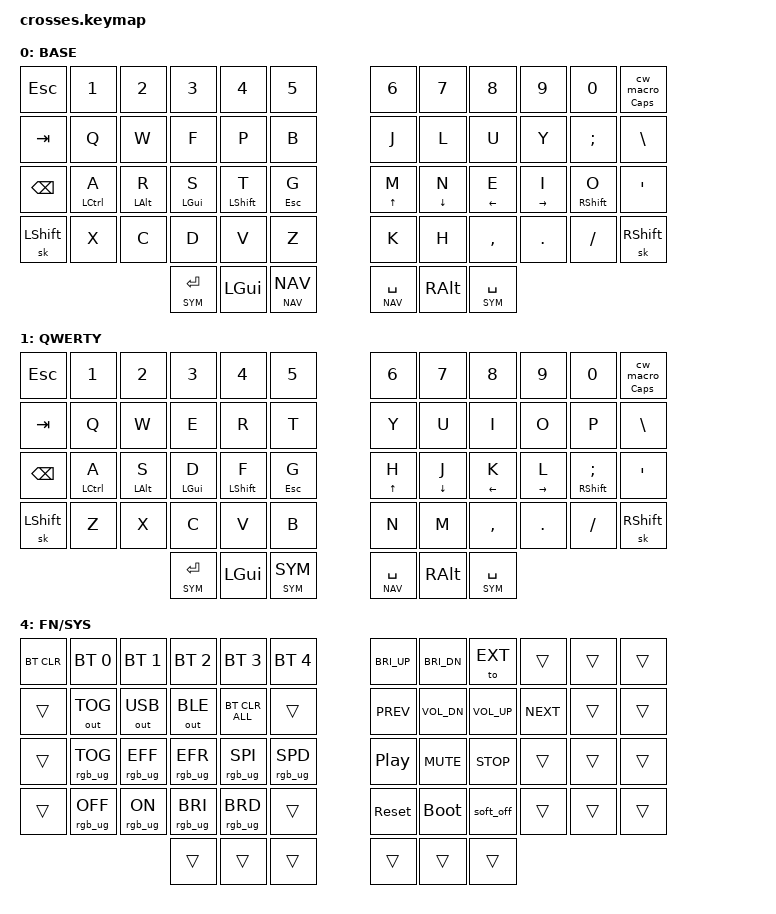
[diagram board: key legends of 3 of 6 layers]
#include <behaviors.dtsi>
#include <dt-bindings/zmk/bt.h>
#include <dt-bindings/zmk/keys.h>
#include <dt-bindings/zmk/outputs.h>
#include <dt-bindings/zmk/pointing.h>
#include <dt-bindings/zmk/rgb.h>
#include <input/processors.dtsi>

#define BASE   0
#define QWERTY 1
#define NAV    2
#define SYM    3
#define FN     4
#define EXT    5

#define LMODS  &kp LCTRL &kp LALT &kp LGUI &kp LSHFT
#define EDIT   &kp K_UNDO &kp K_CUT &kp K_COPY &kp K_PASTE &kp K_REDO

&soft_off { hold-time-ms = <2000>; };

&caps_word { continue-list = <UNDERSCORE MINUS BACKSPACE DELETE>; };

&sk { ignore-modifiers; };

/ {
    chosen { zmk,physical-layout = &gggw_crosses_54_layout; };

    conditional_layers {
        compatible = "zmk,conditional-layers";
        tri_layer {
            if-layers = <NAV SYM>;
            then-layer = <FN>;
        };
    };

    macros {
        cw_macro: cw_macro {
            compatible = "zmk,behavior-macro-one-param";
            #binding-cells = <1>;
            bindings = <&caps_word>;
        };
    };

    behaviors {
        hml: home_row_mod_left {
            compatible = "zmk,behavior-hold-tap";
            #binding-cells = <2>;
            flavor = "balanced";
            tapping-term-ms = <220>;
            quick-tap-ms = <175>;
            require-prior-idle-ms = <150>;
            bindings = <&sk>, <&kp>;
            hold-trigger-key-positions = <
                6  7  8  9  10 11 
                18 19 20 21 22 23 
                30 31 32 33 34 35 
                42 43 44 45 46 47 
                51 52 53
                25 26 27 28
            >;
            hold-trigger-on-release;
        };

        hsl: home_shift_left {
            compatible = "zmk,behavior-hold-tap";
            #binding-cells = <2>;
            flavor = "balanced";
            tapping-term-ms = <220>;
            quick-tap-ms = <175>;
            require-prior-idle-ms = <0>;
            bindings = <&sk>, <&kp>;
            hold-trigger-key-positions = <
                6  7  8  9  10 11 
                18 19 20 21 22 23 
                30 31 32 33 34 35 
                42 43 44 45 46 47 
                51 52 53
                25 26 27 28
            >;
            hold-trigger-on-release;
        };

        hmr: home_row_mod_right {
            compatible = "zmk,behavior-hold-tap";
            #binding-cells = <2>;
            flavor = "balanced";
            tapping-term-ms = <220>;
            quick-tap-ms = <175>;
            require-prior-idle-ms = <0>;
            bindings = <&sk>, <&kp>;
            hold-trigger-key-positions = <
                0  1  2  3  4  5
                12 13 14 15 16 17
                24 25 26 27 28 29
                36 37 38 39 40 41
                48 49 50
            >;
            hold-trigger-on-release;
        };

        hra: home_row_arrow {
            compatible = "zmk,behavior-hold-tap";
            #binding-cells = <2>;
            flavor = "balanced";
            tapping-term-ms = <200>;
            quick-tap-ms = <175>;
            require-prior-idle-ms = <150>;
            bindings = <&kp>, <&kp>;
            hold-trigger-key-positions = <
                0  1  2  3  4  5
                12 13 14 15 16 17
                24 25 26 27 28 29
                36 37 38 39 40 41
                48 49 50
            >;
            hold-trigger-on-release;
        };

        hla: home_left_arrow {
            compatible = "zmk,behavior-hold-tap";
            #binding-cells = <2>;
            flavor = "balanced";
            tapping-term-ms = <200>;
            quick-tap-ms = <175>;
            require-prior-idle-ms = <0>;
            bindings = <&kp>, <&kp>;
            hold-trigger-key-positions = <
                6  7  8  9  10 11 
                18 19 20 21 22 23 
                30 31 32 33 34 35 
                42 43 44 45 46 47 
                51 52 53
            >;
            hold-trigger-on-release;
        };

        lt_thumb: layer_tap_thumb {
            compatible = "zmk,behavior-hold-tap";
            #binding-cells = <2>;
            flavor = "tap-preferred";
            tapping-term-ms = <180>;
            quick-tap-ms = <150>;
            bindings = <&mo>, <&kp>;
        };

        ltq: layer_tap_or_sticky {
            compatible = "zmk,behavior-hold-tap";
            #binding-cells = <2>;
            flavor = "balanced";
            tapping-term-ms = <200>;
            quick-tap-ms = <0>;
            bindings = <&mo>, <&sl>;
        };

        kp_slh: kp_tap_sticky_layer_hold {
            compatible = "zmk,behavior-hold-tap";
            #binding-cells = <2>;
            flavor = "balanced";
            tapping-term-ms = <150>;
            quick-tap-ms = <120>;
            require-prior-idle-ms = <100>;
            bindings = <&sl>, <&kp>;
        };

        cw_caps: caps_word_tap_caps_hold {
            compatible = "zmk,behavior-hold-tap";
            #binding-cells = <2>;
            flavor = "tap-preferred";
            tapping-term-ms = <200>;
            quick-tap-ms = <150>;
            bindings = <&kp>, <&cw_macro>;
        };
    };

    keymap {
        compatible = "zmk,keymap";

        base_layer {
            display-name = "BASE";
            bindings = <
&kp ESC        &kp N1         &kp N2         &kp N3        &kp N4              &kp N5            &kp N6              &kp N7         &kp N8        &kp N9         &kp N0            &cw_caps CAPS 0
&kp TAB        &kp Q          &kp W          &kp F         &kp P               &kp B             &kp J               &kp L          &kp U         &kp Y          &kp SEMI          &kp BSLH
&kp BACKSPACE  &hml LCTRL A   &hml LALT R   &hml LGUI S   &hsl LSHFT T         &hla ESC G        &hra UP M           &hra DOWN N    &hra LEFT E   &hra RIGHT I   &hmr RSHFT O      &kp APOS
&sk LSHFT      &kp X          &kp C          &kp D         &kp V               &kp Z             &kp K               &kp H          &kp COMMA     &kp DOT        &kp FSLH          &sk RSHFT
                                            &kp_slh SYM ENTER &kp LGUI        &ltq NAV NAV       &kp_slh NAV SPACE   &kp RALT             &lt_thumb SYM SPACE
            >;
        };

        qwerty_layer {
            display-name = "QWERTY";
            bindings = <
&kp ESC    &kp N1         &kp N2        &kp N3         &kp N4              &kp N5            &kp N6              &kp N7         &kp N8        &kp N9         &kp N0            &cw_caps CAPS 0
&kp TAB    &kp Q          &kp W         &kp E          &kp R               &kp T             &kp Y               &kp U          &kp I         &kp O          &kp P             &kp BSLH
&kp BACKSPACE  &hml LCTRL A   &hml LALT S   &hml LGUI D   &hsl LSHFT F  &hla ESC G        &hra UP H          &hra DOWN J      &hra LEFT K   &hra RIGHT L    &hmr RSHFT SEMI   &kp APOS
&sk LSHFT  &kp Z          &kp X         &kp C          &kp V               &kp B             &kp N               &kp M          &kp COMMA     &kp DOT        &kp FSLH          &sk RSHFT
                                        &kp_slh SYM ENTER &kp LGUI         &ltq SYM SYM      &kp_slh NAV SPACE   &kp RALT              &lt_thumb SYM SPACE
            >;
        };

        nav_layer {
            display-name = "NAV";
            bindings = <
&trans     &kp F1      &kp F2      &kp F3      &kp F4      &kp F5      &kp F6      &kp F7     &kp F8     &kp F9     &kp F10     &kp F11
&trans     &kp ESC     &mkp LCLK   &mkp MCLK   &mkp RCLK   &mkp MB4    &kp PG_UP   &kp N7     &kp N8     &kp N9     &kp MINUS   &kp F12
&trans     LMODS                                           &mkp MB5    &kp N4     &kp N5     &kp N6     &kp PLUS    &kp EQUAL
&trans     EDIT                                                        &kp N1     &kp N2     &kp N3     &kp ASTRK   &kp ENTER
                                   &trans      &trans      &trans      &trans     &kp DOT    &kp N0
            >;
        };

        sym_layer {
            display-name = "SYM";
            bindings = <
&trans     &kp N1      &kp N2      &kp N3      &kp N4      &kp N5      &kp N6       &kp N7       &kp N8       &kp N9       &kp N0       &trans
&kp TILDE  &kp EXCL    &kp AT      &kp HASH    &kp DLLR    &kp PRCNT   &kp CARET    &kp AMPS     &kp ASTRK    &kp LPAR     &kp RPAR     &kp COLON
&kp GRAVE  LMODS                                           &kp DQT     &kp PLUS     &kp EQUAL    &kp LBRC     &kp RBRC     &kp MINUS    &kp SEMI
&trans     &kp UNDER   &kp LT      &tog QWERTY &kp GT      &kp BSLH    &kp SLASH    &kp QMARK    &kp LBKT     &kp RBKT     &kp UNDER    &trans
                                   &trans      &trans      &trans      &trans       &trans       &trans
            >;
        };

        fn_layer {
            display-name = "FN/SYS";
            bindings = <
&bt BT_CLR &bt BT_SEL 0     &bt BT_SEL 1      &bt BT_SEL 2     &bt BT_SEL 3     &bt BT_SEL 4      &kp C_BRI_UP  &kp C_BRI_DN  &to EXT      &trans  &trans  &trans
&trans     &out OUT_TOG     &out OUT_USB      &out OUT_BLE     &bt BT_CLR_ALL   &trans            &kp C_PREV    &kp C_VOL_DN  &kp C_VOL_UP &kp C_NEXT &trans &trans
&trans     &rgb_ug RGB_TOG  &rgb_ug RGB_EFF   &rgb_ug RGB_EFR  &rgb_ug RGB_SPI  &rgb_ug RGB_SPD   &kp C_PP      &kp C_MUTE    &kp C_STOP   &trans  &trans  &trans
&trans     &rgb_ug RGB_OFF  &rgb_ug RGB_ON    &rgb_ug RGB_BRI  &rgb_ug RGB_BRD  &trans            &sys_reset    &bootloader   &soft_off    &trans  &trans  &trans
                                              &trans           &trans           &trans            &trans        &trans        &trans
            >;
        };

        ext_layer {
            display-name = "EXT";
            bindings = <
&to BASE   &kp PSCRN     &kp SLCK      &kp PAUSE_BREAK  &kp KP_NUM    &trans          &kp INS       &kp HOME      &kp PG_UP     &trans        &trans        &trans
&trans     &kp F11       &kp F12       &kp K_APP        &kp CAPS      &trans          &kp DEL       &kp END       &kp PG_DN     &trans        &trans        &trans
&trans     LMODS                                                      &trans          &kp LEFT      &kp DOWN      &kp UP        &kp RIGHT     &trans        &trans
&trans     EDIT                                                                       &kp K_FIND    &kp C_AL_LOCK &trans        &trans        &trans        &trans
                                       &to BASE         &trans        &trans          &to BASE      &trans        &trans
            >;
        };
    };
};


